# ATA5833 device description
Architecture: AVR8; Family: megaAVR
Registers are 8-bit, access not given, no defined reset value unless marked. A register's access mark holds for its fields unless they carry their own. Offsets are from the block's base; [hi:lo] are bit positions.

## CRC
Instances: CRC 0x00
0x49 CRCDIR — CRC Data Input Register
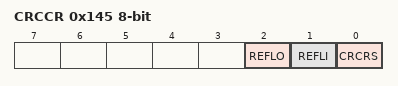
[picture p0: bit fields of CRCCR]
0x145 CRCCR — CRC Control Register
  [2] REFLO — Reflect Data Output Byte
  [1] REFLI — Reflect Data Input Byte
  [0] CRCRS — CRC Data Register Reset
0x146 CRCDOR — CRC Data Output Register

## DEBOUNCE
Instances: DEBOUNCE 0x00
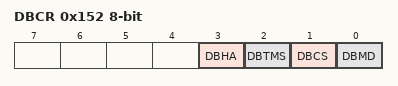
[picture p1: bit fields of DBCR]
0x152 DBCR — DeBounce Control Register
  [3] DBHA — Debounce Handshake Active
  [2] DBTMS — Debounce Timer Mask Select
  [1] DBCS — Debounce Clock Select
  [0] DBMD — Debounce Mode
0x153 DBTC — Debounce Timer Compare Register
0x154 DBENB — DeBounce Enable Port B
0x155 DBENC bits used 5:0 — DeBounce Enable Port C

## DEBUG
Instances: DEBUG 0x00
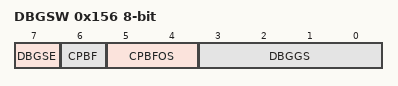
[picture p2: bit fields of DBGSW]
0x156 DBGSW — Debugging Support Switch
  [7] DBGSE — Debugging Support Switch Enable
  [6] CPBF — CPU Busy Flag
  [5:4] CPBFOS — CPU Busy Flag Output Select
  [3:0] DBGGS — Debugging Support Group Select

## DEMOD
Instances: DEMOD 0x00
0x9F RXFOB — Received Frequency Offset vs Intermediate Frequency on path B
0xA0 RXFOA — Received Frequency Offset vs Intermediate Frequency on path A
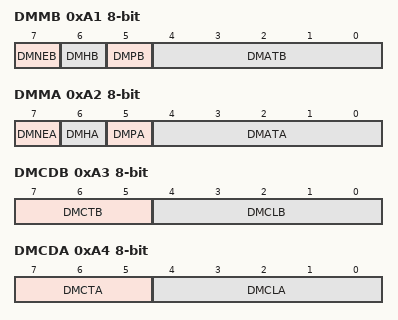
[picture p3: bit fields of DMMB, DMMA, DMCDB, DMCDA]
0xA1 DMMB — Demodulator Mode for Path B
  [7] DMNEB — Demodulator NRZ Enable for path B
  [6] DMHB — Demodulator Hold Mode for path B
  [5] DMPB — Demodulator Data Polarity Selection for path B
  [4:0] DMATB — Demodulator Amplitude Threshold for path B
0xA2 DMMA — Demodulator Mode for path A
  [7] DMNEA — Demodulator NRZ Enable for path A
  [6] DMHA — Demodulator Hold Mode for path A
  [5] DMPA — Demodulator Data Polarity Selection for path A
  [4:0] DMATA — Demodulator Amplitude Threshold for path A
0xA3 DMCDB — Demodulator Carrier Detect for path B
  [7:5] DMCTB — Demodulator Carrier Detect Time for path B
  [4:0] DMCLB — Demodulator Carrier Detect Limit for path B
0xA4 DMCDA — Demodulator Carrier Detect for path A
  [7:5] DMCTA — Demodulator Carrier Detect Time for path A
  [4:0] DMCLA — Demodulator Carrier Detect Limit for path A
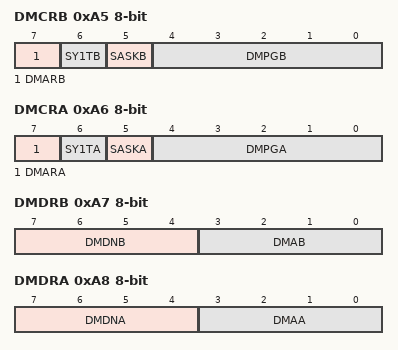
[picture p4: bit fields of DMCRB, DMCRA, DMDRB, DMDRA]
0xA5 DMCRB — Demodulator Control Register for path B
  [7] DMARB — Demodulator automatic restart on path B
  [6] SY1TB — Symbol check with only 1T on path B
  [5] SASKB — Select ASK input for path B
  [4:0] DMPGB — Demodulator PLL loop gain for path B
0xA6 DMCRA — Demodulator Control Register for path A
  [7] DMARA — Demodulator automatic restart on path A
  [6] SY1TA — Symbol check with only 1T on path A
  [5] SASKA — Select ASK input for path A
  [4:0] DMPGA — Demodulator PLL loop gain for path A
0xA7 DMDRB — Demodulator Data Rate on path B
  [7:4] DMDNB — Demodulator Downsampling on path B
  [3:0] DMAB — Demodulator Moving Average Data Rate factor on path B
0xA8 DMDRA — Demodulator Data Rate on path A
  [7:4] DMDNA — Demodulator Downsampling on path A
  [3:0] DMAA — Demodulator Moving Average Data Rate factor on path A

## DFIFO
Instances: DFIFO 0x00
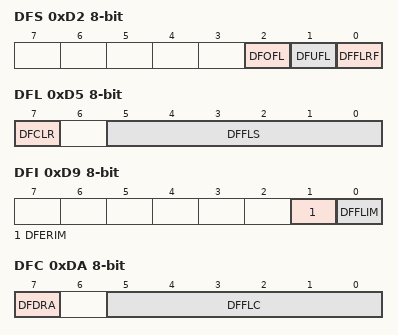
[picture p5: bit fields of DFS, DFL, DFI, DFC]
0xD2 DFS — Data FIFO Status Register
  [2] DFOFL — Data FIFO Overflow Flag
  [1] DFUFL — Data FIFO Underflow Flag
  [0] DFFLRF — Data FIFO Fill-Level Reached Status Flag
0xD3 DFTL 16-bit bits used 11:0 — Data FIFO Telegram Length
0xD5 DFL — Data FIFO Fill Level Register
  [7] DFCLR — Data FIFO Clear
  [5:0] DFFLS — Data FIFO Fill Level Status
0xD6 DFWP — Data FIFO Write Pointer
  [5:0] DFWP
0xD7 DFRP — Data FIFO Read Pointer
  [5:0] DFRP
0xD8 DFD — Data FIFO Data Register
0xD9 DFI — Data FIFO Interrupt Mask Register
  [1] DFERIM — Data FIFO Error Interrupt Mask
  [0] DFFLIM — Data FIFO Fill-level Interrupt Mask
0xDA DFC — Data FIFO Configuration Register
  [7] DFDRA — Data FIFO Direct Read Access Operational Mode
  [5:0] DFFLC — Data FIFO Fill-Level Configuration

## EEPROM
Instances: EEPROM 0x00
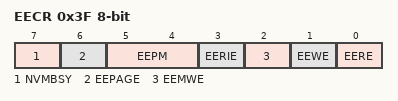
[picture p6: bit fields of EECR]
0x3F EECR — EEPROM Control Register
  [7] NVMBSY — Non-volatile memory busy
  [6] EEPAGE — EEPROM page access (multiple bytes access mode)
  [5:4] EEPM — EEPROM Programming Mode
    0=Erase and Write in one operation; 1=Erase Only; 2=Write Only
  [3] EERIE — EEPROM Ready Interrupt Enable
  [2] EEMWE — EEPROM Master Write Enable
  [1] EEWE — EEPROM Write Enable
  [0] EERE — EEPROM Read Enable
0x40 EEDR — EEPROM Data Register
0x41 EEAR 16-bit bits used 10:0 — EEPROM Address Register
0x43 EEPR — EEPROM Protection Register
  [3:0] EEAP — EEPROM Access Protection
0x159 EECR2 — EEPROM Control Register 2
  [0] EEBRE — EEPROM Burst Read Enable
